AUTOSAR XML (schema 4-2-2)
standard types defined: sint16, uint16, uint32, uint8, sint16_DataConstr, uint16_DataConstr, uint32_DataConstr, uint8_DataConstr, boolean
package /IoHwAb/Interface
  4 x client server interface:
    IoHwAb_IoSigAdc
      operation Adc_Get: possible-error=IoHwAb_IoSigAdc/E_NOT_OK
        arg id_u16: type=ImplementationDataTypes/uint16, direction=IN, server-argument-impl-policy=USE-ARGUMENT-TYPE
        arg val_s16: type=sint16, direction=OUT, server-argument-impl-policy=USE-ARGUMENT-TYPE
      operation AdcFac_Get: possible-error=IoHwAb_IoSigAdc/E_NOT_OK
        arg id_u16: type=ImplementationDataTypes/uint16, direction=IN, server-argument-impl-policy=USE-ARGUMENT-TYPE
        arg val_s16: type=sint16, direction=OUT, server-argument-impl-policy=USE-ARGUMENT-TYPE
      operation AdcVRMBatt_Get: possible-error=IoHwAb_IoSigAdc/E_NOT_OK
        arg id_u16: type=ImplementationDataTypes/uint16, direction=IN, server-argument-impl-policy=USE-ARGUMENT-TYPE
        arg val_u8: type=ImplementationDataTypes/uint8, direction=OUT, server-argument-impl-policy=USE-ARGUMENT-TYPE
      error E_NOT_OK: error-code=1
    IoHwAb_IoSigDio
      operation Di_Get: possible-error=IoHwAb_IoSigDio/E_NOT_OK
        arg id_u16: type=ImplementationDataTypes/uint16, direction=IN, server-argument-impl-policy=USE-ARGUMENT-TYPE
        arg val_u8: type=ImplementationDataTypes/uint8, direction=OUT, server-argument-impl-policy=USE-ARGUMENT-TYPE
      operation Do_Set: possible-error=IoHwAb_IoSigDio/E_NOT_OK
        arg id_u16: type=ImplementationDataTypes/uint16, direction=IN, server-argument-impl-policy=USE-ARGUMENT-TYPE
        arg val_u8: type=ImplementationDataTypes/uint8, direction=IN, server-argument-impl-policy=USE-ARGUMENT-TYPE
      error E_NOT_OK: error-code=1
    IoHwAb_IoSigIcu
      operation Icu_GetPerdAndDuty: possible-error=IoHwAb_IoSigIcu/E_NOT_OK
        arg id_u16: type=ImplementationDataTypes/uint16, direction=IN, server-argument-impl-policy=USE-ARGUMENT-TYPE
        arg duty_u32: type=uint32, direction=OUT, server-argument-impl-policy=USE-ARGUMENT-TYPE
        arg period_u32: type=uint32, direction=OUT, server-argument-impl-policy=USE-ARGUMENT-TYPE
      error E_NOT_OK: error-code=1
    IoHwAb_IoSigPwm
      operation Pwm_SetDuty: possible-error=IoHwAb_IoSigPwm/E_NOT_OK
        arg id_u16: type=ImplementationDataTypes/uint16, direction=IN, server-argument-impl-policy=USE-ARGUMENT-TYPE
        arg duty_u16: type=ImplementationDataTypes/uint16, direction=IN, server-argument-impl-policy=USE-ARGUMENT-TYPE
      operation Pwm_SetPerd: possible-error=IoHwAb_IoSigPwm/E_NOT_OK
        arg id_u16: type=ImplementationDataTypes/uint16, direction=IN, server-argument-impl-policy=USE-ARGUMENT-TYPE
        arg perd_u32: type=uint32, direction=IN, server-argument-impl-policy=USE-ARGUMENT-TYPE
      operation Pwm_SetPerdAndDuty: possible-error=IoHwAb_IoSigPwm/E_NOT_OK
        arg id_u16: type=ImplementationDataTypes/uint16, direction=IN, server-argument-impl-policy=USE-ARGUMENT-TYPE
        arg perd_u32: type=uint32, direction=IN, server-argument-impl-policy=USE-ARGUMENT-TYPE
        arg duty_u16: type=ImplementationDataTypes/uint16, direction=IN, server-argument-impl-policy=USE-ARGUMENT-TYPE
      error E_NOT_OK: error-code=1
package /UAES/ASW/ApplicationDataTypes
  app type Fac_q0p001_u16: category=VALUE, sw-calibration-access=READ-WRITE, compu {phys=raw*0.001 for raw -INF..INF}, range phys 0..65.535
package /UAES/ASW/CompuMethods
  compu method CM_boolean: 0=FALSE, 1=TRUE
package /UAES/ASW/DataConstrs
  range DC_boolean: raw 0..1
  range DC_uint16: phys 0..6553.5, raw 0..65535
  range DC_uint8: raw 0..255
package /UAES/ASW/DataTypeMappingSets
  data type mapping set DTMS_INL_DD: data-type-map{application-data-type=Fac_q0p001_u16, implementation-data-type=ImplementationDataTypes/uint16}
package /UAES/ASW/PortInterfaces
  36 x sender receiver interface:
    BattU_buExcdSmallRng: invalidation-policy{data-element=BattU_buExcdSmallRng/Val, handle-invalid=DONT-INVALIDATE}
      data Val: sw-calibration-access=READ-ONLY, type=boolean
    BattU_VrmFac1: invalidation-policy{data-element=BattU_VrmFac1/Val, handle-invalid=DONT-INVALIDATE}
      data Val: sw-calibration-access=READ-ONLY, type=Fac_q0p001_u16
    BattU_VrmFac2: invalidation-policy{data-element=BattU_VrmFac2/Val, handle-invalid=DONT-INVALIDATE}
      data Val: sw-calibration-access=READ-ONLY, type=Fac_q0p001_u16
    BattU_VrmFac3: invalidation-policy{data-element=BattU_VrmFac3/Val, handle-invalid=DONT-INVALIDATE}
      data Val: sw-calibration-access=READ-ONLY, type=Fac_q0p001_u16
    gASI_bACDisChrgLampSw: invalidation-policy{data-element=gASI_bACDisChrgLampSw/Val, handle-invalid=DONT-INVALIDATE}
      data Val: sw-calibration-access=READ-ONLY, type=boolean
    gASI_bHazardLampSw: invalidation-policy{data-element=gASI_bHazardLampSw/Val, handle-invalid=DONT-INVALIDATE}
      data Val: sw-calibration-access=READ-ONLY, type=boolean
    gASI_bWindowdInhibitSw: invalidation-policy{data-element=val, handle-invalid=DONT-INVALIDATE}
      data val: sw-calibration-access=READ-ONLY, type=boolean
    gASI_u16ShiftAngleHall1PwmFreq: invalidation-policy{data-element=gASI_u16ShiftAngleHall1PwmFreq/Val, handle-invalid=DONT-INVALIDATE}
      data Val: sw-calibration-access=READ-ONLY, type=ImplementationDataTypes/uint16
    gASI_u16ShiftAngleHall2PwmFreq: invalidation-policy{data-element=gASI_u16ShiftAngleHall2PwmFreq/Val, handle-invalid=DONT-INVALIDATE}
      data Val: sw-calibration-access=READ-ONLY, type=ImplementationDataTypes/uint16
    gASI_u8GearnParkSw1: invalidation-policy{data-element=gASI_u8GearnParkSw1/Val, handle-invalid=DONT-INVALIDATE}
      data Val: sw-calibration-access=READ-ONLY, type=ImplementationDataTypes/uint8
    gASI_u8GearnParkSw2: invalidation-policy{data-element=gASI_u8GearnParkSw2/Val, handle-invalid=DONT-INVALIDATE}
      data Val: sw-calibration-access=READ-ONLY, type=ImplementationDataTypes/uint8
    gASI_u8ShiftAngleHall1PwmDuty: invalidation-policy{data-element=gASI_u8ShiftAngleHall1PwmDuty/Val, handle-invalid=DONT-INVALIDATE}
      data Val: sw-calibration-access=READ-ONLY, type=ImplementationDataTypes/uint8
    gASI_u8ShiftAngleHall2PwmDuty: invalidation-policy{data-element=gASI_u8ShiftAngleHall2PwmDuty/Val, handle-invalid=DONT-INVALIDATE}
      data Val: sw-calibration-access=READ-ONLY, type=ImplementationDataTypes/uint8
    gINL_bACDisChrglightOutput: invalidation-policy{data-element=gINL_bACDisChrglightOutput/Val, handle-invalid=DONT-INVALIDATE}
      data Val: sw-calibration-access=READ-ONLY, type=boolean
    gINL_bACPlugEleclockLightOutput: invalidation-policy{data-element=gINL_bACPlugEleclockLightOutput/Val, handle-invalid=DONT-INVALIDATE}
      data Val: sw-calibration-access=READ-ONLY, type=boolean
    gINL_bFLCourtesyLightOutput: invalidation-policy{data-element=gINL_bFLCourtesyLightOutput/Val, handle-invalid=DONT-INVALIDATE}
      data Val: sw-calibration-access=READ-ONLY, type=boolean
    gINL_bFRCourtesyLightOutput: invalidation-policy{data-element=gINL_bFRCourtesyLightOutput/Val, handle-invalid=DONT-INVALIDATE}
      data Val: sw-calibration-access=READ-ONLY, type=boolean
    gINL_bGearDIndicateLightEnable: invalidation-policy{data-element=gINL_bGearDIndicateLightEnable/Val, handle-invalid=DONT-INVALIDATE}
      data Val: sw-calibration-access=READ-ONLY, type=boolean
    gINL_bGearNIndicateLightEnable: invalidation-policy{data-element=gINL_bGearNIndicateLightEnable/Val, handle-invalid=DONT-INVALIDATE}
      data Val: sw-calibration-access=READ-ONLY, type=boolean
    gINL_bGearPIndicateLightEnable: invalidation-policy{data-element=gINL_bGearPIndicateLightEnable/Val, handle-invalid=DONT-INVALIDATE}
      data Val: sw-calibration-access=READ-ONLY, type=boolean
    gINL_bGearRIndicateLightEnable: invalidation-policy{data-element=gINL_bGearRIndicateLightEnable/Val, handle-invalid=DONT-INVALIDATE}
      data Val: sw-calibration-access=READ-ONLY, type=boolean
    gINL_bRLCourtesyLightOutput: invalidation-policy{data-element=gINL_bRLCourtesyLightOutput/Val, handle-invalid=DONT-INVALIDATE}
      data Val: sw-calibration-access=READ-ONLY, type=boolean
    gINL_bRRCourtesyLightOutput: invalidation-policy{data-element=gINL_bRRCourtesyLightOutput/Val, handle-invalid=DONT-INVALIDATE}
      data Val: sw-calibration-access=READ-ONLY, type=boolean
    gINL_u8BackgroundLightBrightness: invalidation-policy{data-element=gINL_u8BackgroundLightBrightness/Val, handle-invalid=DONT-INVALIDATE}
      data Val: sw-calibration-access=READ-ONLY, type=ImplementationDataTypes/uint8
    gINL_u8BatterySaveOutput: invalidation-policy{data-element=gINL_u8BatterySaveOutput/Val, handle-invalid=DONT-INVALIDATE}
      data Val: sw-calibration-access=READ-ONLY, type=ImplementationDataTypes/uint8
    gINL_u8HazardSwBackLightOutput: invalidation-policy{data-element=gINL_u8HazardSwBackLightOutput/Val, handle-invalid=DONT-INVALIDATE}
      data Val: sw-calibration-access=READ-ONLY, type=ImplementationDataTypes/uint8
    gINL_u8IALPower_L: invalidation-policy{data-element=gINL_u8IALPower_L/Val, handle-invalid=DONT-INVALIDATE}
      data Val: sw-calibration-access=READ-ONLY, type=ImplementationDataTypes/uint8
    gINL_u8IALPower_R: invalidation-policy{data-element=gINL_u8IALPower_R/Val, handle-invalid=DONT-INVALIDATE}
      data Val: sw-calibration-access=READ-ONLY, type=ImplementationDataTypes/uint8
    gINL_u8IndicateLightBrightness: invalidation-policy{data-element=gINL_u8IndicateLightBrightness/Val, handle-invalid=DONT-INVALIDATE}
      data Val: sw-calibration-access=READ-ONLY, type=ImplementationDataTypes/uint8
    gINL_u8LeftBackGroudLightOutput: invalidation-policy{data-element=gINL_u8LeftBackGroudLightOutput/Val, handle-invalid=DONT-INVALIDATE}
      data Val: sw-calibration-access=READ-ONLY, type=ImplementationDataTypes/uint8
    gINL_u8RearBackGroudLightOutput: invalidation-policy{data-element=gINL_u8RearBackGroudLightOutput/Val, handle-invalid=DONT-INVALIDATE}
      data Val: sw-calibration-access=READ-ONLY, type=ImplementationDataTypes/uint8
    gINL_u8RightBackGroundLightOutput: invalidation-policy{data-element=gINL_u8RightBackGroundLightOutput/Val, handle-invalid=DONT-INVALIDATE}
      data Val: sw-calibration-access=READ-ONLY, type=ImplementationDataTypes/uint8
    gINL_u8RoofLightOutput: invalidation-policy{data-element=gINL_u8RoofLightOutput/Val, handle-invalid=DONT-INVALIDATE}
      data Val: sw-calibration-access=READ-ONLY, type=ImplementationDataTypes/uint8
    gINL_u8StepLightOutput: invalidation-policy{data-element=gINL_u8StepLightOutput/Val, handle-invalid=DONT-INVALIDATE}
      data Val: sw-calibration-access=READ-ONLY, type=ImplementationDataTypes/uint8
    gINL_u8TrunkLampOutput: invalidation-policy{data-element=gINL_u8TrunkLampOutput/Val, handle-invalid=DONT-INVALIDATE}
      data Val: sw-calibration-access=READ-ONLY, type=ImplementationDataTypes/uint8
    gINL_u8WndInhibitLampOutput: invalidation-policy{data-element=gINL_u8WndInhibitLampOutput/Val, handle-invalid=DONT-INVALIDATE}
      data Val: sw-calibration-access=READ-ONLY, type=ImplementationDataTypes/uint8
package /UAES/ASW/SwComponentTypes
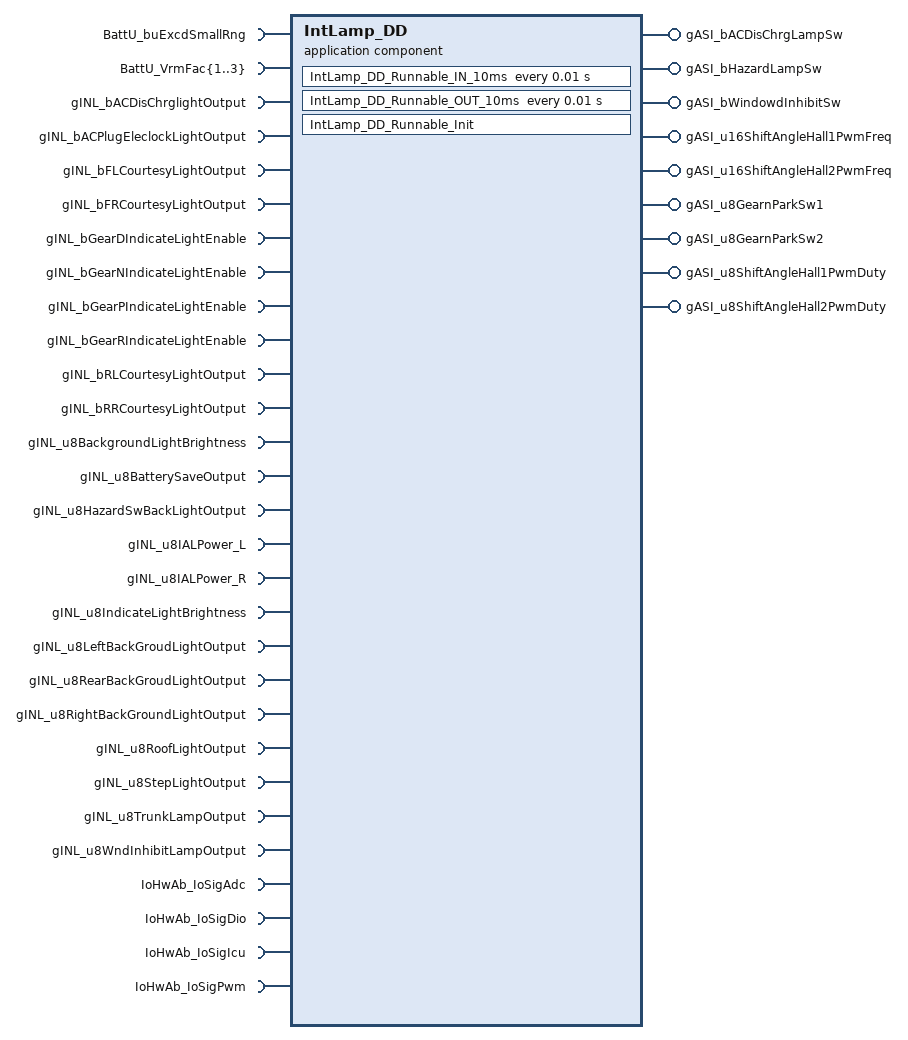
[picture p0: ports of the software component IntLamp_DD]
  application sw component type IntLamp_DD
    9 x provide port:
      gASI_bACDisChrgLampSw: nonqueued-sender-com-spec{data-element=gASI_bACDisChrgLampSw/Val, init-value=0}, provided-interface=gASI_bACDisChrgLampSw
      gASI_bHazardLampSw: nonqueued-sender-com-spec{data-element=gASI_bHazardLampSw/Val, init-value=0}, provided-interface=gASI_bHazardLampSw
      gASI_bWindowdInhibitSw: nonqueued-sender-com-spec{data-element=val, init-value=0}, provided-interface=gASI_bWindowdInhibitSw
      gASI_u16ShiftAngleHall1PwmFreq: nonqueued-sender-com-spec{data-element=gASI_u16ShiftAngleHall1PwmFreq/Val, init-value=0}, provided-interface=gASI_u16ShiftAngleHall1PwmFreq
      gASI_u16ShiftAngleHall2PwmFreq: nonqueued-sender-com-spec{data-element=gASI_u16ShiftAngleHall2PwmFreq/Val, init-value=0}, provided-interface=gASI_u16ShiftAngleHall2PwmFreq
      gASI_u8GearnParkSw1: nonqueued-sender-com-spec{data-element=gASI_u8GearnParkSw1/Val, init-value=0}, provided-interface=gASI_u8GearnParkSw1
      gASI_u8GearnParkSw2: nonqueued-sender-com-spec{data-element=gASI_u8GearnParkSw2/Val, init-value=0}, provided-interface=gASI_u8GearnParkSw2
      gASI_u8ShiftAngleHall1PwmDuty: nonqueued-sender-com-spec{data-element=gASI_u8ShiftAngleHall1PwmDuty/Val, init-value=0}, provided-interface=gASI_u8ShiftAngleHall1PwmDuty
      gASI_u8ShiftAngleHall2PwmDuty: nonqueued-sender-com-spec{data-element=gASI_u8ShiftAngleHall2PwmDuty/Val, init-value=0}, provided-interface=gASI_u8ShiftAngleHall2PwmDuty
    31 x require port:
      BattU_buExcdSmallRng: nonqueued-receiver-com-spec{data-element=BattU_buExcdSmallRng/Val, filter=data-filter-type=ALWAYS, init-value=0}, required-interface=BattU_buExcdSmallRng
      BattU_VrmFac{1..3}: nonqueued-receiver-com-spec{data-element=BattU_VrmFac{1..3}/Val, filter=data-filter-type=ALWAYS, init-value=0}, required-interface=BattU_VrmFac{1..3}
      gINL_bACDisChrglightOutput: nonqueued-receiver-com-spec{data-element=gINL_bACDisChrglightOutput/Val, filter=data-filter-type=ALWAYS, init-value=0}, required-interface=gINL_bACDisChrglightOutput
      gINL_bACPlugEleclockLightOutput: nonqueued-receiver-com-spec{data-element=gINL_bACPlugEleclockLightOutput/Val, filter=data-filter-type=ALWAYS, init-value=0}, required-interface=gINL_bACPlugEleclockLightOutput
      gINL_bFLCourtesyLightOutput: nonqueued-receiver-com-spec{data-element=gINL_bFLCourtesyLightOutput/Val, filter=data-filter-type=ALWAYS, init-value=0}, required-interface=gINL_bFLCourtesyLightOutput
      gINL_bFRCourtesyLightOutput: nonqueued-receiver-com-spec{data-element=gINL_bFRCourtesyLightOutput/Val, filter=data-filter-type=ALWAYS, init-value=0}, required-interface=gINL_bFRCourtesyLightOutput
      gINL_bGearDIndicateLightEnable: nonqueued-receiver-com-spec{data-element=gINL_bGearDIndicateLightEnable/Val, filter=data-filter-type=ALWAYS, init-value=0}, required-interface=gINL_bGearDIndicateLightEnable
      gINL_bGearNIndicateLightEnable: nonqueued-receiver-com-spec{data-element=gINL_bGearNIndicateLightEnable/Val, filter=data-filter-type=ALWAYS, init-value=0}, required-interface=gINL_bGearNIndicateLightEnable
      gINL_bGearPIndicateLightEnable: nonqueued-receiver-com-spec{data-element=gINL_bGearPIndicateLightEnable/Val, filter=data-filter-type=ALWAYS, init-value=0}, required-interface=gINL_bGearPIndicateLightEnable
      gINL_bGearRIndicateLightEnable: nonqueued-receiver-com-spec{data-element=gINL_bGearRIndicateLightEnable/Val, filter=data-filter-type=ALWAYS, init-value=0}, required-interface=gINL_bGearRIndicateLightEnable
      gINL_bRLCourtesyLightOutput: nonqueued-receiver-com-spec{data-element=gINL_bRLCourtesyLightOutput/Val, filter=data-filter-type=ALWAYS, init-value=0}, required-interface=gINL_bRLCourtesyLightOutput
      gINL_bRRCourtesyLightOutput: nonqueued-receiver-com-spec{data-element=gINL_bRRCourtesyLightOutput/Val, filter=data-filter-type=ALWAYS, init-value=0}, required-interface=gINL_bRRCourtesyLightOutput
      gINL_u8BackgroundLightBrightness: nonqueued-receiver-com-spec{data-element=gINL_u8BackgroundLightBrightness/Val, filter=data-filter-type=ALWAYS, init-value=0}, required-interface=gINL_u8BackgroundLightBrightness
      gINL_u8BatterySaveOutput: nonqueued-receiver-com-spec{data-element=gINL_u8BatterySaveOutput/Val, filter=data-filter-type=ALWAYS, init-value=0}, required-interface=gINL_u8BatterySaveOutput
      gINL_u8HazardSwBackLightOutput: nonqueued-receiver-com-spec{data-element=gINL_u8HazardSwBackLightOutput/Val, filter=data-filter-type=ALWAYS, init-value=0}, required-interface=gINL_u8HazardSwBackLightOutput
      gINL_u8IALPower_L: nonqueued-receiver-com-spec{data-element=gINL_u8IALPower_L/Val, filter=data-filter-type=ALWAYS, init-value=0}, required-interface=gINL_u8IALPower_L
      gINL_u8IALPower_R: nonqueued-receiver-com-spec{data-element=gINL_u8IALPower_R/Val, filter=data-filter-type=ALWAYS, init-value=0}, required-interface=gINL_u8IALPower_R
      gINL_u8IndicateLightBrightness: nonqueued-receiver-com-spec{data-element=gINL_u8IndicateLightBrightness/Val, filter=data-filter-type=ALWAYS, init-value=0}, required-interface=gINL_u8IndicateLightBrightness
      gINL_u8LeftBackGroudLightOutput: nonqueued-receiver-com-spec{data-element=gINL_u8LeftBackGroudLightOutput/Val, filter=data-filter-type=ALWAYS, init-value=0}, required-interface=gINL_u8LeftBackGroudLightOutput
      gINL_u8RearBackGroudLightOutput: nonqueued-receiver-com-spec{data-element=gINL_u8RearBackGroudLightOutput/Val, filter=data-filter-type=ALWAYS, init-value=0}, required-interface=gINL_u8RearBackGroudLightOutput
      gINL_u8RightBackGroundLightOutput: nonqueued-receiver-com-spec{data-element=gINL_u8RightBackGroundLightOutput/Val, filter=data-filter-type=ALWAYS, init-value=0}, required-interface=gINL_u8RightBackGroundLightOutput
      gINL_u8RoofLightOutput: nonqueued-receiver-com-spec{data-element=gINL_u8RoofLightOutput/Val, filter=data-filter-type=ALWAYS, init-value=0}, required-interface=gINL_u8RoofLightOutput
      gINL_u8StepLightOutput: nonqueued-receiver-com-spec{data-element=gINL_u8StepLightOutput/Val, filter=data-filter-type=ALWAYS, init-value=0}, required-interface=gINL_u8StepLightOutput
      gINL_u8TrunkLampOutput: nonqueued-receiver-com-spec{data-element=gINL_u8TrunkLampOutput/Val, filter=data-filter-type=ALWAYS, init-value=0}, required-interface=gINL_u8TrunkLampOutput
      gINL_u8WndInhibitLampOutput: nonqueued-receiver-com-spec{data-element=gINL_u8WndInhibitLampOutput/Val, filter=data-filter-type=ALWAYS, init-value=0}, required-interface=gINL_u8WndInhibitLampOutput
      IoHwAb_IoSigAdc: required-com-specs=[Adc_Get, AdcFac_Get, AdcVRMBatt_Get], required-interface=IoHwAb_IoSigAdc
      IoHwAb_IoSigDio: required-com-specs=[Di_Get, Do_Set], required-interface=IoHwAb_IoSigDio
      IoHwAb_IoSigIcu: client-com-spec=Icu_GetPerdAndDuty, required-interface=IoHwAb_IoSigIcu
      IoHwAb_IoSigPwm: required-com-specs=[Pwm_SetDuty, Pwm_SetPerd, Pwm_SetPerdAndDuty], required-interface=IoHwAb_IoSigPwm
    behavior IntLamp_DD_InternalBehavior: data-type-mapping=DTMS_INL_DD
      timing event TMT_IntLamp_DD_Runnable_IN_10ms: start-on-event=IntLamp_DD_Runnable_IN_10ms, period=0.01
      init event IntLamp_DD_Runnable_InitEvent: start-on-event=IntLamp_DD_Runnable_Init
      timing event TMT_IntLamp_DD_Runnable_OUT_10ms: start-on-event=IntLamp_DD_Runnable_OUT_10ms, period=0.01
      runnable IntLamp_DD_Runnable_IN_10ms
        data-receive-point-by-arguments:
          4 x access:
            IN_BattU_buExcdSmallRng_Val: accessed-variable=BattU_buExcdSmallRng.Val
            IN_BattU_VrmFac{1..3}_Val: accessed-variable=BattU_VrmFac{1..3}.Val
        data-send-points:
          9 x access:
            OUT_gASI_bACDisChrgLampSw_Val: accessed-variable=gASI_bACDisChrgLampSw.Val
            OUT_gASI_bHazardLampSw_Val: accessed-variable=gASI_bHazardLampSw.Val
            OUT_gASI_bWindowdInhibitSw_val: accessed-variable=gASI_bWindowdInhibitSw.val
            OUT_gASI_u16ShiftAngleHall1PwmFreq_Val: accessed-variable=gASI_u16ShiftAngleHall1PwmFreq.Val
            OUT_gASI_u16ShiftAngleHall2PwmFreq_Val: accessed-variable=gASI_u16ShiftAngleHall2PwmFreq.Val
            OUT_gASI_u8GearnParkSw1_Val: accessed-variable=gASI_u8GearnParkSw1.Val
            OUT_gASI_u8GearnParkSw2_Val: accessed-variable=gASI_u8GearnParkSw2.Val
            OUT_gASI_u8ShiftAngleHall1PwmDuty_Val: accessed-variable=gASI_u8ShiftAngleHall1PwmDuty.Val
            OUT_gASI_u8ShiftAngleHall2PwmDuty_Val: accessed-variable=gASI_u8ShiftAngleHall2PwmDuty.Val
        4 x sync call, all with timeout=0:
          SC_IoHwAb_IoSigAdc_AdcFac_Get: operation=IoHwAb_IoSigAdc.AdcFac_Get
          SC_IoHwAb_IoSigAdc_AdcVRMBatt_Get: operation=IoHwAb_IoSigAdc.AdcVRMBatt_Get
          SC_IoHwAb_IoSigDio_Di_Get: operation=IoHwAb_IoSigDio.Di_Get
          SC_IoHwAb_IoSigIcu_Icu_GetPerdAndDuty: operation=IoHwAb_IoSigIcu.Icu_GetPerdAndDuty
      runnable IntLamp_DD_Runnable_Init
      runnable IntLamp_DD_Runnable_OUT_10ms
        data-receive-point-by-arguments:
          23 x access:
            IN_gINL_bACDisChrglightOutput_Val: accessed-variable=gINL_bACDisChrglightOutput.Val
            IN_gINL_bACPlugEleclockLightOutput_Val: accessed-variable=gINL_bACPlugEleclockLightOutput.Val
            IN_gINL_bFLCourtesyLightOutput_Val: accessed-variable=gINL_bFLCourtesyLightOutput.Val
            IN_gINL_bFRCourtesyLightOutput_Val: accessed-variable=gINL_bFRCourtesyLightOutput.Val
            IN_gINL_bGearDIndicateLightEnable_Val: accessed-variable=gINL_bGearDIndicateLightEnable.Val
            IN_gINL_bGearNIndicateLightEnable_Val: accessed-variable=gINL_bGearNIndicateLightEnable.Val
            IN_gINL_bGearPIndicateLightEnable_Val: accessed-variable=gINL_bGearPIndicateLightEnable.Val
            IN_gINL_bGearRIndicateLightEnable_Val: accessed-variable=gINL_bGearRIndicateLightEnable.Val
            IN_gINL_bRLCourtesyLightOutput_Val: accessed-variable=gINL_bRLCourtesyLightOutput.Val
            IN_gINL_bRRCourtesyLightOutput_Val: accessed-variable=gINL_bRRCourtesyLightOutput.Val
            IN_gINL_u8BackgroundLightBrightness_Val: accessed-variable=gINL_u8BackgroundLightBrightness.Val
            IN_gINL_u8BatterySaveOutput_Val: accessed-variable=gINL_u8BatterySaveOutput.Val
            IN_gINL_u8HazardSwBackLightOutput_Val: accessed-variable=gINL_u8HazardSwBackLightOutput.Val
            IN_gINL_u8IALPower_L_Val: accessed-variable=gINL_u8IALPower_L.Val
            IN_gINL_u8IALPower_R_Val: accessed-variable=gINL_u8IALPower_R.Val
            IN_gINL_u8IndicateLightBrightness_Val: accessed-variable=gINL_u8IndicateLightBrightness.Val
            IN_gINL_u8LeftBackGroudLightOutput_Val: accessed-variable=gINL_u8LeftBackGroudLightOutput.Val
            IN_gINL_u8RearBackGroudLightOutput_Val: accessed-variable=gINL_u8RearBackGroudLightOutput.Val
            IN_gINL_u8RightBackGroundLightOutput_Val: accessed-variable=gINL_u8RightBackGroundLightOutput.Val
            IN_gINL_u8RoofLightOutput_Val: accessed-variable=gINL_u8RoofLightOutput.Val
            IN_gINL_u8StepLightOutput_Val: accessed-variable=gINL_u8StepLightOutput.Val
            IN_gINL_u8TrunkLampOutput_Val: accessed-variable=gINL_u8TrunkLampOutput.Val
            IN_gINL_u8WndInhibitLampOutput_Val: accessed-variable=gINL_u8WndInhibitLampOutput.Val
        sync call SC_IoHwAb_IoSigDio_Do_Set: operation=IoHwAb_IoSigDio.Do_Set, timeout=0
        sync call SC_IoHwAb_IoSigPwm_Pwm_SetDuty: operation=IoHwAb_IoSigPwm.Pwm_SetDuty, timeout=0
  swc implementation IntLamp_DD_Implementation: behavior=IntLamp_DD_InternalBehavior
    code-descriptors:
      code Default: artifact-descriptors=autosar-engineering-object={short-label=Default, category=SWSRC}
package /UAES/ASW/Units
  unit NoUnit: factor-si-to-unit=1, offset-si-to-unit=0
